# EFR32BG13P532F512GM32 register map
File version: 5.8.2
CPU: CM4 r0p1, little endian, MPU, FPU, 3 interrupt priority bits
Registers are 32-bit, read-write, reset 0x0 unless marked. A register's access mark holds for its fields unless they carry their own. Offsets are from the block's base; [hi:lo] are bit positions; {n}, {i} and the like mark numbered series.

## TRNG0
Base 0x4001D000
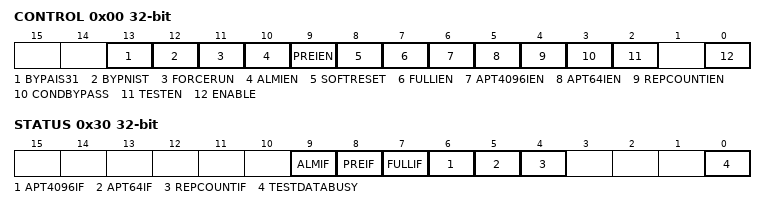
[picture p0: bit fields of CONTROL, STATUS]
0x00 CONTROL — Main Control Register
  [13] BYPAIS31 — AIS31 Start-up Test Bypass.
  [12] BYPNIST — NIST Start-up Test Bypass.
  [11] FORCERUN — Oscillator Force Run
  [10] ALMIEN — Interrupt enable for AIS31 noise alarm
  [9] PREIEN — Interrupt enable for AIS31 preliminary noise alarm
  [8] SOFTRESET — Software Reset
  [7] FULLIEN — Interrupt Enable for FIFO Full
  [6] APT4096IEN — Interrupt Enable for Adaptive Proportion Test Failure (4096-sample Window)
  [5] APT64IEN — Interrupt Enable for Adaptive Proportion Test Failure (64-sample Window)
  [4] REPCOUNTIEN — Interrupt Enable for Repetition Count Test Failure
  [3] CONDBYPASS — Conditioning Bypass
  [2] TESTEN — Test Enable
  [0] ENABLE — TRNG Module Enable
0x04 FIFOLEVEL ro read-has-side-effects
  [31:0] VALUE — FIFO Level
0x0C FIFODEPTH ro reset 0x40
  [31:0] VALUE — FIFO Depth.
{0x10+4i} KEY{i} (i=0..3) — Key Register {i}
  [31:0] VALUE — Key {i}
0x20 TESTDATA
  [31:0] VALUE — Test data input to conditioning function or to the continuous tests
0x30 STATUS
  [9] ALMIF ro — AIS31 Noise Alarm interrupt status
  [8] PREIF — AIS31 Preliminary Noise Alarm interrupt status
  [7] FULLIF ro — FIFO Full Interrupt Status
  [6] APT4096IF ro — Adaptive Proportion test failure (4096-sample window) interrupt status
  [5] APT64IF ro — Adaptive Proportion test failure (64-sample window) interrupt status
  [4] REPCOUNTIF ro — Repetition Count Test Interrupt Status
  [0] TESTDATABUSY ro
0x34 INITWAITVAL reset 0xFF — Initial Wait Counter
  [7:0] VALUE — Wait counter value
0x100 FIFO ro read-has-side-effects — FIFO Data
  [31:0] VALUE — FIFO Read Data

## ITM — Instrumentation Trace Macrocell
Base 0xE0000E00
0x00 TER — Trace Enable Register
0x40 TPR — Trace Privilege Register
0x80 TCR — Trace Control Register

## TPIU — Trace Port Interface Unit
Base 0xE0040000
0x10 ACPR reset not defined — Asynchronous Clock Prescaler Register
0xF0 SPPR reset not defined — Selected Pin Protocol Register
  [1:0] TXMODE
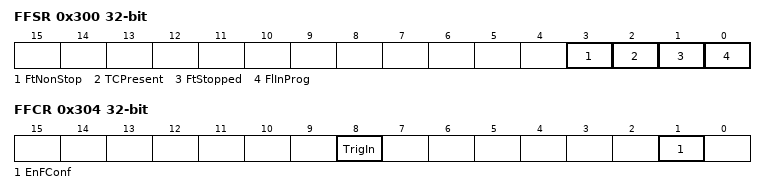
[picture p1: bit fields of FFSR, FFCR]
0x300 FFSR ro reset not defined — Formatter and Flush Status Register
  [3] FtNonStop, [2] TCPresent, [1] FtStopped, [0] FlInProg
0x304 FFCR reset not defined — Formatter and Flush Control Register
  [8] TrigIn, [1] EnFConf
0x308 FSCR ro reset not defined — Formatter Synchronization Counter Register

## DBGMCU — MCU debug component
Base 0xE0042000
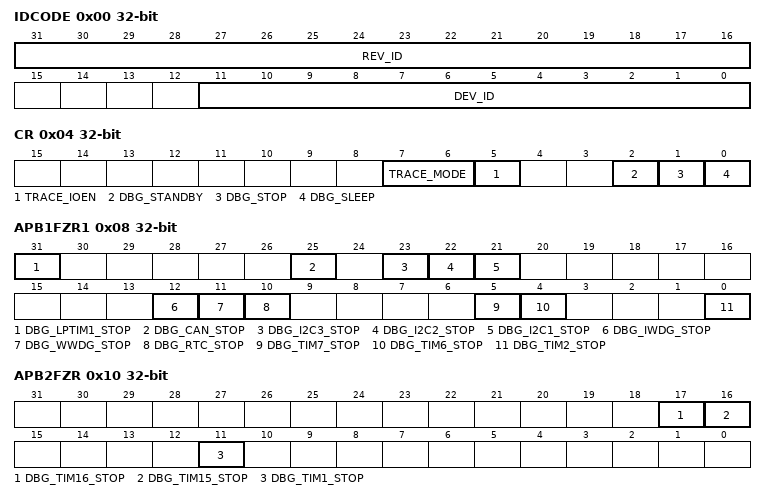
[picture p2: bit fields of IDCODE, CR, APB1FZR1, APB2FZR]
0x00 IDCODE ro — DBGMCU_IDCODE
  [31:16] REV_ID — Revision identifie
  [11:0] DEV_ID — Device identifier
0x04 CR — Debug MCU configuration register
  [7:6] TRACE_MODE — Trace pin assignment control
  [5] TRACE_IOEN — Trace pin assignment control
  [2] DBG_STANDBY — Debug Standby mode
  [1] DBG_STOP — Debug Stop mode
  [0] DBG_SLEEP — Debug Sleep mode
0x08 APB1FZR1 — Debug MCU APB1 freeze register1
  [31] DBG_LPTIM1_STOP — LPTIM1 counter stopped when core is halted
  [25] DBG_CAN_STOP — bxCAN stopped when core is halted
  [23] DBG_I2C3_STOP — I2C3 SMBUS timeout counter stopped when core is halted
  [22] DBG_I2C2_STOP — I2C2 SMBUS timeout counter stopped when core is halted
  [21] DBG_I2C1_STOP — I2C1 SMBUS timeout counter stopped when core is halted
  [12] DBG_IWDG_STOP — Independent watchdog counter stopped when core is halted
  [11] DBG_WWDG_STOP — Window watchdog counter stopped when core is halted
  [10] DBG_RTC_STOP — RTC counter stopped when core is halted
  [5] DBG_TIM7_STOP — TIM7 counter stopped when core is halted
  [4] DBG_TIM6_STOP — TIM6 counter stopped when core is halted
  [0] DBG_TIM2_STOP — TIM2 counter stopped when core is halted
0x0C APB1FZR2 — Debug MCU APB1 freeze register 2
  [5] DBG_LPTIM2_STOP — LPTIM2 counter stopped when core is halted
0x10 APB2FZR — Debug MCU APB2 freeze register
  [17] DBG_TIM16_STOP — TIM16 counter stopped when core is halted
  [16] DBG_TIM15_STOP — TIM15 counter stopped when core is halted
  [11] DBG_TIM1_STOP — TIM1 counter stopped when core is halted
